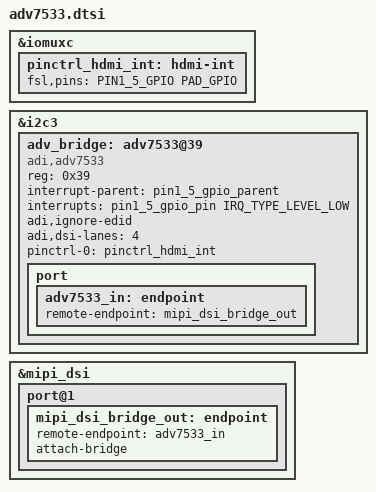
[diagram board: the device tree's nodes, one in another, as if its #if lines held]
/*
 * Copyright 2020 Keith & Koep GmbH
 *
 */

&iomuxc {
	pinctrl_hdmi_int: hdmi-int 	{
		fsl,pins = < PIN1_5_GPIO		PAD_GPIO >; /* HDMI_INT */
	};
};

&i2c3 {
	adv_bridge: adv7533@39 {
		compatible = "adi,adv7533";
		reg = <0x39>;

		interrupt-parent = <pin1_5_gpio_parent>;
		interrupts = <pin1_5_gpio_pin IRQ_TYPE_LEVEL_LOW>;

		adi,ignore-edid;
		adi,dsi-lanes = <4>;
        pinctrl-names = "default";
		pinctrl-0 = <&pinctrl_hdmi_int>;        
		status = "okay";

		port {
			adv7533_in: endpoint {
				remote-endpoint = <&mipi_dsi_bridge_out>;
			};
		};
	};
};
/************************************************************************/
#if defined (__DTS_MYON2_PINFUNC_H) || defined (__DTS_MYON2NANO_PINFUNC_H)
&mipi_dsi {
	status = "okay";

	port@1 {
		mipi_dsi_bridge_out: endpoint {
			remote-endpoint = <&adv7533_in>;
            attach-bridge;
		};
	};
};
#endif
/************************************************************************/

